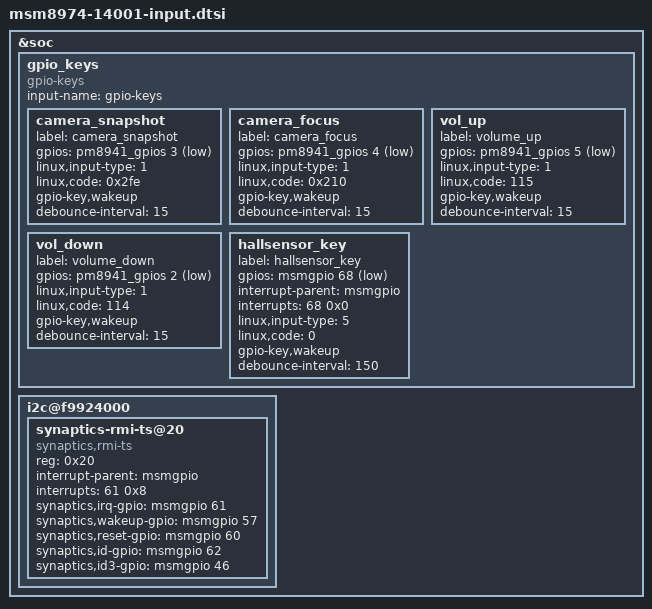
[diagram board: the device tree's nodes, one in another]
/* Copyright (c) 2012-2013, The Linux Foundation. All rights reserved.
 *
 * This program is free software; you can redistribute it and/or modify
 * it under the terms of the GNU General Public License version 2 and
 * only version 2 as published by the Free Software Foundation.
 *
 * This program is distributed in the hope that it will be useful,
 * but WITHOUT ANY WARRANTY; without even the implied warranty of
 * MERCHANTABILITY or FITNESS FOR A PARTICULAR PURPOSE.  See the
 * GNU General Public License for more details.
 */

&soc {
	gpio_keys {
		compatible = "gpio-keys";
		input-name = "gpio-keys";
		status = "ok";

		camera_snapshot {
			label = "camera_snapshot";
			gpios = <&pm8941_gpios 3 0x1>;
			linux,input-type = <1>;
			linux,code = <0x2fe>;
			gpio-key,wakeup;
			debounce-interval = <15>;
		};

		camera_focus {
			label = "camera_focus";
			gpios = <&pm8941_gpios 4 0x1>;
			linux,input-type = <1>;
			linux,code = <0x210>;
			gpio-key,wakeup;
			debounce-interval = <15>;
		};

		vol_up {
			label = "volume_up";
			gpios = <&pm8941_gpios 5 0x1>;
			linux,input-type = <1>;
			linux,code = <115>;
			gpio-key,wakeup;
			debounce-interval = <15>;
		};

		vol_down {
			label = "volume_down";
			gpios = <&pm8941_gpios 2 0x1>;
			linux,input-type = <1>;
			linux,code = <114>;
			gpio-key,wakeup;
			debounce-interval = <15>;
		};

		hallsensor_key {
			label = "hallsensor_key";
			gpios = <&msmgpio 68 1>;
			interrupt-parent = <&msmgpio>;
			interrupts = <68 0x0>;
			linux,input-type = <5>;
			linux,code = <0>;
			gpio-key,wakeup;
			debounce-interval = <150>;
		};
	};

	i2c@f9924000 {
		synaptics-rmi-ts@20 {
			compatible = "synaptics,rmi-ts";
			reg = <0x20>;
			interrupt-parent = <&msmgpio>;
			interrupts = <61 0x8>;
			synaptics,irq-gpio = <&msmgpio 61 0x00>;
			synaptics,wakeup-gpio = <&msmgpio 57 0x00>;
			synaptics,reset-gpio = <&msmgpio 60 0x00>;
			synaptics,id-gpio = <&msmgpio 62 0x00>;
			synaptics,id3-gpio = <&msmgpio 46 0x00>;
		};
	};
};
